AUTOSAR XML (schema 00046)
package /ComponentTypes
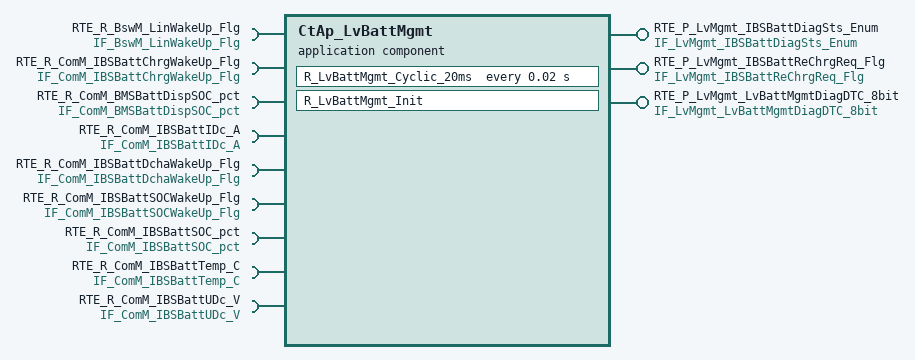
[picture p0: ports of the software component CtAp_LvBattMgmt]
  application sw component type CtAp_LvBattMgmt
    provide port RTE_P_LvMgmt_IBSBattDiagSts_Enum: nonqueued-sender-com-spec{data-element=tec_LvMgmt_IBSBattDiagSts_Enum, init-value=0}, provided-interface=IF_LvMgmt_IBSBattDiagSts_Enum
    provide port RTE_P_LvMgmt_IBSBattReChrgReq_Flg: nonqueued-sender-com-spec{data-element=tec_LvMgmt_IBSBattReChrgReq_Flg, init-value=0}, provided-interface=IF_LvMgmt_IBSBattReChrgReq_Flg
    provide port RTE_P_LvMgmt_LvBattMgmtDiagDTC_8bit: nonqueued-sender-com-spec{data-element=tec_LvMgmt_LvBattMgmtDiagDTC_8bit, init-value=0}, provided-interface=IF_LvMgmt_LvBattMgmtDiagDTC_8bit
    9 x require port:
      RTE_R_BswM_LinWakeUp_Flg: nonqueued-receiver-com-spec{data-element=tec_BswM_LinWakeUp_Flg, filter=data-filter-type=ALWAYS, init-value=0}, required-interface=IF_BswM_LinWakeUp_Flg
      RTE_R_ComM_IBSBattChrgWakeUp_Flg: nonqueued-receiver-com-spec{data-element=tec_ComM_IBSBattChrgWakeUp_Flg, filter=data-filter-type=ALWAYS, init-value=0}, required-interface=IF_ComM_IBSBattChrgWakeUp_Flg
      RTE_R_ComM_BMSBattDispSOC_pct: nonqueued-receiver-com-spec{data-element=tec_ComM_BMSBattDispSOC_pct, filter=data-filter-type=ALWAYS, init-value=0}, required-interface=IF_ComM_BMSBattDispSOC_pct
      RTE_R_ComM_IBSBattIDc_A: nonqueued-receiver-com-spec{data-element=tec_ComM_IBSBattIDc_A, filter=data-filter-type=ALWAYS, init-value=0}, required-interface=IF_ComM_IBSBattIDc_A
      RTE_R_ComM_IBSBattDchaWakeUp_Flg: nonqueued-receiver-com-spec{data-element=tec_ComM_IBSBattDchaWakeUp_Flg, filter=data-filter-type=ALWAYS, init-value=0}, required-interface=IF_ComM_IBSBattDchaWakeUp_Flg
      RTE_R_ComM_IBSBattSOCWakeUp_Flg: nonqueued-receiver-com-spec{data-element=tec_ComM_IBSBattSOCWakeUp_Flg, filter=data-filter-type=ALWAYS, init-value=0}, required-interface=IF_ComM_IBSBattSOCWakeUp_Flg
      RTE_R_ComM_IBSBattSOC_pct: nonqueued-receiver-com-spec{data-element=tec_ComM_IBSBattSOC_pct, filter=data-filter-type=ALWAYS, init-value=0}, required-interface=IF_ComM_IBSBattSOC_pct
      RTE_R_ComM_IBSBattTemp_C: nonqueued-receiver-com-spec{data-element=tec_ComM_IBSBattTemp_C, filter=data-filter-type=ALWAYS, init-value=0}, required-interface=IF_ComM_IBSBattTemp_C
      RTE_R_ComM_IBSBattUDc_V: nonqueued-receiver-com-spec{data-element=tec_ComM_IBSBattUDc_V, filter=data-filter-type=ALWAYS, init-value=0}, required-interface=IF_ComM_IBSBattUDc_V
    behavior CtAp_LvBattMgmt_InternalBehavior
      init event CtAp_LvBattMgmt_InitEvent: start-on-event=R_LvBattMgmt_Init
      timing event TMT_R_LvBattMgmt_Cyclic_20ms: start-on-event=R_LvBattMgmt_Cyclic_20ms, period=0.02
      runnable R_LvBattMgmt_Init
      runnable R_LvBattMgmt_Cyclic_20ms
        data-receive-point-by-arguments:
          9 x access:
            REC_RTE_R_BswM_LinWakeUp_Flg_tec_BswM_LinWakeUp_Flg: accessed-variable=RTE_R_BswM_LinWakeUp_Flg.tec_BswM_LinWakeUp_Flg
            REC_RTE_R_ComM_BMSBattDispSOC_pct_tec_ComM_BMSBattDispSOC_pct: accessed-variable=RTE_R_ComM_BMSBattDispSOC_pct.tec_ComM_BMSBattDispSOC_pct
            REC_RTE_R_ComM_IBSBattChrgWakeUp_Flg_tec_ComM_IBSBattChrgWakeUp_Flg: accessed-variable=RTE_R_ComM_IBSBattChrgWakeUp_Flg.tec_ComM_IBSBattChrgWakeUp_Flg
            REC_RTE_R_ComM_IBSBattDchaWakeUp_Flg_tec_ComM_IBSBattDchaWakeUp_Flg: accessed-variable=RTE_R_ComM_IBSBattDchaWakeUp_Flg.tec_ComM_IBSBattDchaWakeUp_Flg
            REC_RTE_R_ComM_IBSBattIDc_A_tec_ComM_IBSBattIDc_A: accessed-variable=RTE_R_ComM_IBSBattIDc_A.tec_ComM_IBSBattIDc_A
            REC_RTE_R_ComM_IBSBattSOCWakeUp_Flg_tec_ComM_IBSBattSOCWakeUp_Flg: accessed-variable=RTE_R_ComM_IBSBattSOCWakeUp_Flg.tec_ComM_IBSBattSOCWakeUp_Flg
            REC_RTE_R_ComM_IBSBattSOC_pct_tec_ComM_IBSBattSOC_pct: accessed-variable=RTE_R_ComM_IBSBattSOC_pct.tec_ComM_IBSBattSOC_pct
            REC_RTE_R_ComM_IBSBattTemp_C_tec_ComM_IBSBattTemp_C: accessed-variable=RTE_R_ComM_IBSBattTemp_C.tec_ComM_IBSBattTemp_C
            REC_RTE_R_ComM_IBSBattUDc_V_tec_ComM_IBSBattUDc_V: accessed-variable=RTE_R_ComM_IBSBattUDc_V.tec_ComM_IBSBattUDc_V
        data-send-points:
          access SEND_RTE_P_LvMgmt_IBSBattDiagSts_Enum_tec_LvMgmt_IBSBattDiagSts_Enum: accessed-variable=RTE_P_LvMgmt_IBSBattDiagSts_Enum.tec_LvMgmt_IBSBattDiagSts_Enum
          access SEND_RTE_P_LvMgmt_IBSBattReChrgReq_Flg_tec_LvMgmt_IBSBattReChrgReq_Flg: accessed-variable=RTE_P_LvMgmt_IBSBattReChrgReq_Flg.tec_LvMgmt_IBSBattReChrgReq_Flg
          access SEND_RTE_P_LvMgmt_LvBattMgmtDiagDTC_8bit_tec_LvMgmt_LvBattMgmtDiagDTC_8bit: accessed-variable=RTE_P_LvMgmt_LvBattMgmtDiagDTC_8bit.tec_LvMgmt_LvBattMgmtDiagDTC_8bit
  swc implementation CtAp_LvBattMgmt_Implementation: behavior=CtAp_LvBattMgmt_InternalBehavior
    code-descriptors:
      code Default: artifact-descriptors=autosar-engineering-object=category=SWOBJ
